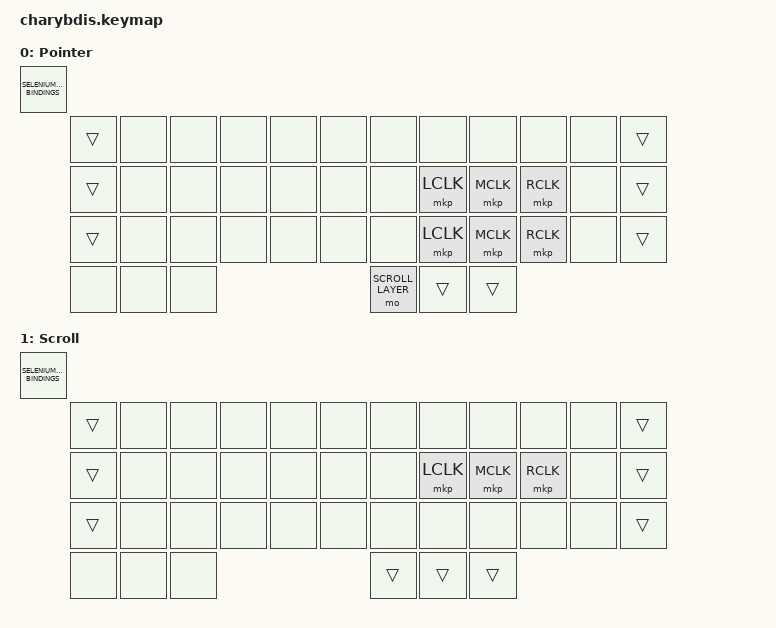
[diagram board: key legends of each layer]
#define MACOS
#define KB_LAYOUT_ERGOL
#define HT_TWO_THUMB_KEYS
#define VIM_NAVIGATION
#define POINTER_LAYER EXTRA_LAYERS_START_INDEX
#define SCROLL_LAYER (EXTRA_LAYERS_START_INDEX + 1)
#define CHARY_EXTRA_LEFT &mo POINTER_LAYER

#include <dt-bindings/zmk/mouse.h>
#include <dt-bindings/zmk/pointing.h>

#define SELENIUM_KEYMAP_BINDINGS(LOUT1,  LROW1,  RROW1,  ROUT1, \
                                 LOUT2,  LROW2,  RROW2,  ROUT2, \
                                 LOUT3,  LROW3,  RROW3,  ROUT3, \
                                 LT1, LT2, LT3,  RT3, RT2, RT1) \
    &none &none &none &none &none &none &none &none &none &none &none &none \
    LOUT1 LROW1 RROW1 ROUT1 \
    LOUT2 LROW2 RROW2 ROUT2 \
    LOUT3 LROW3 RROW3 ROUT3 \
    CHARY_EXTRA_LEFT LT1 LT2 RT2 RT3 \
    &none &none &none

#include "../include/selenium/selenium.keymap"

&function_layer {
  bindings = <SELENIUM_KEYMAP_BINDINGS(
    &trans  ,  &kp F1  &kp F2  &kp F3  &kp F4  &none   ,   &none &kp C_PREV     &kp C_VOL_UP     &kp C_BRI_UP        &kp SLCK           ,  &trans ,
    &trans  ,  &kp F5  &kp F6  &kp F7  &kp F8  &none   ,   &none &hrm LALT C_PP &hrm RCTL C_MUTE &hrm RGUI C_AL_LOCK &hrm LSHIFT PSCRN  ,  &trans ,
    &trans  ,  &kp F9  &kp F10 &kp F11 &kp F12 &none   ,   &none &kp C_NEXT     &kp C_VOL_DN     &kp C_BRI_DN        &kp INS            ,  &trans ,
              &trans , &bootloader , &none   ,   &sys_reset , &studio_unlock , &none
  )>;
};

/ {
  keymap {
    compatible = "zmk,keymap";

    pointer_layer {
      display-name = "Pointer";
      bindings = <SELENIUM_KEYMAP_BINDINGS(
        &trans  , &none &none &none &none &none , &none &none &none &none &none , &trans,
        &trans  , &none &none &none &none &none , &none &mkp LCLK &mkp MCLK &mkp RCLK &none , &trans,
        &trans  , &none &none &none &none &none , &none &mkp LCLK &mkp MCLK &mkp RCLK &none , &trans,
        &none , &none , &none , &mo SCROLL_LAYER , &trans , &trans
      )>;
    };

    scroll_layer {
      display-name = "Scroll";
      bindings = <SELENIUM_KEYMAP_BINDINGS(
        &trans  , &none &none &none &none &none , &none &none &none &none &none , &trans,
        &trans  , &none &none &none &none &none , &none &mkp LCLK &mkp MCLK &mkp RCLK &none , &trans,
        &trans  , &none &none &none &none &none , &none &none &none &none &none , &trans,
        &none , &none , &none , &trans , &trans , &trans
      )>;
    };
  };
};
